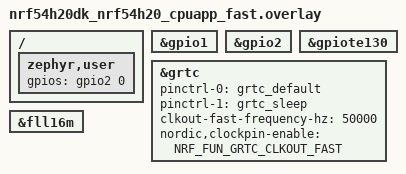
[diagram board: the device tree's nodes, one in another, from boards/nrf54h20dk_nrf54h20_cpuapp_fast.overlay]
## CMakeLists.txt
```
# SPDX-License-Identifier: LicenseRef-Nordic-5-Clause

cmake_minimum_required(VERSION 3.20.0)

find_package(Zephyr REQUIRED HINTS $ENV{ZEPHYR_BASE})
project(grtc_clk_out)

FILE(GLOB app_sources src/*.c)
target_sources(app PRIVATE ${app_sources})
```

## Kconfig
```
#
# Copyright (c) 2025 Nordic Semiconductor ASA
#
# SPDX-License-Identifier: LicenseRef-Nordic-5-Clause
#


config TEST_GRTC_FREQUENCY
	int "Expected frequency (Hz) at GRTC output pin"
	default 32768
	help
	  GRTC can output clock signal on dedicated pin.
	  This can be 32768 Hz signal or fast clock which is
	  16 MHz divided by (1..255 * 2).

config TEST_GRTC_TOLERANCE
	int "Amount of additional/missing clock edges"
	default 100
	help
	  Define tolerance for expected number of clock edges
	  counted during 1 second interval.

source "Kconfig.zephyr"
```

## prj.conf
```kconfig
CONFIG_ZTEST=y
CONFIG_SPEED_OPTIMIZATIONS=y
CONFIG_CLOCK_CONTROL=y
```

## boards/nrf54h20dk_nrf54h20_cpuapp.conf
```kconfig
CONFIG_NRF_REGTOOL_VERBOSITY=2
```

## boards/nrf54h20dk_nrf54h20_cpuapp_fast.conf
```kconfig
CONFIG_TEST_GRTC_FREQUENCY=50000
CONFIG_TEST_GRTC_TOLERANCE=500
```

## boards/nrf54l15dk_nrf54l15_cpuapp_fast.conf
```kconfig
CONFIG_TEST_GRTC_FREQUENCY=40000
CONFIG_TEST_GRTC_TOLERANCE=400
```

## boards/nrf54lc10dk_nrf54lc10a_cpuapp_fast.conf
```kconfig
nrf54lv10dk_nrf54lv10a_cpuapp_fast.conf
```

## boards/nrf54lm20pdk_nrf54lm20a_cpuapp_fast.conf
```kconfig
CONFIG_TEST_GRTC_FREQUENCY=32000
CONFIG_TEST_GRTC_TOLERANCE=320
```

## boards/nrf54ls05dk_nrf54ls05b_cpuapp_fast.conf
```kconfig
CONFIG_TEST_GRTC_FREQUENCY=32000
CONFIG_TEST_GRTC_TOLERANCE=360
```

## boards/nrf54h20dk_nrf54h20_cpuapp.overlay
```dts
/*
 * Copyright (c) 2025 Nordic Semiconductor ASA
 *
 * SPDX-License-Identifier: LicenseRef-Nordic-5-Clause
 */

/* Required loopback between:
 * GPIO P0.3 and P0.1 (GRTC 32k; defined @board; no other option)
 */

/ {
	zephyr,user {
		gpios = <&gpio0 3 GPIO_ACTIVE_HIGH>;  /* Connect to dedicated GRTC output */
	};
};

&gpio0 {
	status = "okay";
};

&gpiote130 {
	status = "okay";
};

&grtc {
	pinctrl-0 = <&grtc_default>;
	pinctrl-1 = <&grtc_sleep>;
	pinctrl-names = "default", "sleep";
	clkout-32k;
};

&fll16m {
	status = "okay";
};
```

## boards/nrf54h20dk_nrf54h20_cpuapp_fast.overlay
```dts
/*
 * Copyright (c) 2025 Nordic Semiconductor ASA
 *
 * SPDX-License-Identifier: LicenseRef-Nordic-5-Clause
 */

/* Required loopback between:
 * GPIO P2.0 and P1.8 (GRTC fast; defined @board; can be changed to P2.5 or P9.0)
 */

/ {
	zephyr,user {
		gpios = <&gpio2 0 GPIO_ACTIVE_HIGH>;  /* Connect to dedicated GRTC output */
	};
};

&gpio1 {
	status = "okay";
};

&gpio2 {
	status = "okay";
};

&gpiote130 {
	status = "okay";
};

&grtc {
	pinctrl-0 = <&grtc_default>;
	pinctrl-1 = <&grtc_sleep>;
	pinctrl-names = "default", "sleep";
	clkout-fast-frequency-hz = <50000>;  /* 16 MHz / (160 * 2) */
	nordic,clockpin-enable = <NRF_FUN_GRTC_CLKOUT_FAST>;
};

&fll16m {
	status = "okay";
};
```

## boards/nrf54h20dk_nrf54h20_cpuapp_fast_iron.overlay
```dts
/*
 * Copyright (c) 2025 Nordic Semiconductor ASA
 *
 * SPDX-License-Identifier: LicenseRef-Nordic-5-Clause
 */

/* Required loopback between:
 * GPIO P2.0 and P1.8 (GRTC fast; defined @board; can be changed to P2.5 or P9.0)
 */

/ {
	zephyr,user {
		gpios = <&gpio2 0 GPIO_ACTIVE_HIGH>;  /* Connect to dedicated GRTC output */
	};
};

&gpio1 {
	status = "okay";
};

&gpio2 {
	status = "okay";
};

&gpiote130 {
	status = "okay";
};

&grtc {
	pinctrl-0 = <&grtc_default>;
	pinctrl-1 = <&grtc_sleep>;
	pinctrl-names = "default", "sleep";
	clkout-fast-frequency-hz = <50000>;  /* 16 MHz / (160 * 2) */
	nordic,clockpin-enable = <NRF_FUN_GRTC_CLKOUT_FAST>;
};
```

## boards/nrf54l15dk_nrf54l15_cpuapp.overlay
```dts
/*
 * Copyright (c) 2025 Nordic Semiconductor ASA
 *
 * SPDX-License-Identifier: LicenseRef-Nordic-5-Clause
 */

/* Required loopback between:
 * GPIO P0.0 and P0.4 (GRTC 32k; defined @board; no other option)
 */

/ {
	zephyr,user {
		gpios = <&gpio0 0 GPIO_ACTIVE_HIGH>;  /* Connect to dedicated GRTC output */
	};
};

&gpio0 {
	status = "okay";
};

&gpiote30 {
	status = "okay";
};

&grtc {
	pinctrl-0 = <&grtc_default>;
	pinctrl-1 = <&grtc_sleep>;
	pinctrl-names = "default", "sleep";
	clkout-32k;
};
```

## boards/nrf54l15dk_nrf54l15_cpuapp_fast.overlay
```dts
/*
 * Copyright (c) 2025 Nordic Semiconductor ASA
 *
 * SPDX-License-Identifier: LicenseRef-Nordic-5-Clause
 */

/* Required loopback between:
 * GPIO P1.9 and P1.8 (GRTC fast; defined @board; no other option)
 */

/ {
	zephyr,user {
		gpios = <&gpio1 9 GPIO_ACTIVE_HIGH>;  /* Connect to dedicated GRTC output */
	};
};

&gpio1 {
	status = "okay";
};

&gpiote20 {
	status = "okay";
};

&grtc {
	pinctrl-0 = <&grtc_default>;
	pinctrl-1 = <&grtc_sleep>;
	pinctrl-names = "default", "sleep";
	clkout-fast-frequency-hz = <40000>;  /* 16 MHz / (200 * 2) */
};
```

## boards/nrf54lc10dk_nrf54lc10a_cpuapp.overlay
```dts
/*
 * Copyright (c) 2026 Nordic Semiconductor ASA
 *
 * SPDX-License-Identifier: LicenseRef-Nordic-5-Clause
 */

/* Required loopback between:
 * GPIO P1.16 and P0.4 (GRTC 32k; defined @board; no other option)
 */

/ {
	zephyr,user {
		gpios = <&gpio1 16 GPIO_ACTIVE_HIGH>;  /* Connect to dedicated GRTC output */
	};
};

&gpio1 {
	status = "okay";
};

&grtc {
	pinctrl-0 = <&grtc_default>;
	pinctrl-1 = <&grtc_sleep>;
	pinctrl-names = "default", "sleep";
	clkout-32k;
};
```

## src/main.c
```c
/*
 * Copyright (c) 2025 Nordic Semiconductor ASA
 *
 * SPDX-License-Identifier: LicenseRef-Nordic-5-Clause
 */

#include <zephyr/kernel.h>
#include <zephyr/ztest.h>
#include <zephyr/drivers/gpio.h>
#include <zephyr/drivers/clock_control/nrf_clock_control.h>


static volatile uint32_t count_clk;

static struct gpio_callback clk_cb_data;
static const struct gpio_dt_spec gpio_clk_spec =
	GPIO_DT_SPEC_GET_BY_IDX(DT_PATH(zephyr_user), gpios, 0);

#define GRTC_NODE DT_NODELABEL(grtc)

/* SoCs without an fll16m instance take the HFCLK from the nordic,nrf-clock block,
 * exposed as either an hfclk or an xo node depending on the SoC.
 */
#define HAS_NRF_CLOCK_HFCLK                                                                        \
	(DT_HAS_COMPAT_STATUS_OKAY(nordic_nrf_clock_hfclk) ||                                      \
	 DT_HAS_COMPAT_STATUS_OKAY(nordic_nrf_clock_xo))

#if DT_NODE_HAS_PROP(GRTC_NODE, clkout_fast_frequency_hz)
static struct onoff_client clk_cli;
static volatile bool clock_requested;

/* Callback for clock request. */
static void clock_started_callback(struct onoff_manager *mgr,
				   struct onoff_client *cli,
				   uint32_t state,
				   int res)
{
	(void)mgr;
	(void)cli;
	(void)state;
	(void)res;

	clock_requested = true;
}
#if DT_NODE_HAS_STATUS_OKAY(DT_NODELABEL(fll16m))
#define NODE_HFCLK      DT_NODELABEL(fll16m)
#define HFCLK_FREQUENCY DT_PROP_OR(NODE_HFCLK, frequency, 0)
static const struct device *clk_dev = DEVICE_DT_GET(NODE_HFCLK);
static const struct nrf_clock_spec fll16m_spec = {
	.frequency = HFCLK_FREQUENCY,
};
static const struct nrf_clock_spec *clk_spec = &fll16m_spec;

#elif HAS_NRF_CLOCK_HFCLK
#if defined(CONFIG_CLOCK_CONTROL_NRF)
static struct onoff_manager *clk_mgr;
#else
static const struct device *clk_dev = DEVICE_DT_GET_ONE(COND_CODE_1(NRF_CLOCK_HAS_HFCLK,
								    (nordic_nrf_clock_hfclk),
								    (nordic_nrf_clock_xo)));
static const struct nrf_clock_spec *clk_spec;
#endif
#endif

static int hf_clock_request(void)
{
	sys_notify_init_callback(&clk_cli.notify, clock_started_callback);
#if DT_NODE_HAS_STATUS_OKAY(DT_NODELABEL(fll16m)) || HAS_NRF_CLOCK_HFCLK
#if defined(CONFIG_CLOCK_CONTROL_NRF)
	clock_control_subsys_t subsys = CLOCK_CONTROL_NRF_SUBSYS_HF;

	clk_mgr = z_nrf_clock_control_get_onoff(subsys);
	return onoff_request(clk_mgr, &clk_cli);
#else
	return nrf_clock_control_request(clk_dev, clk_spec, &clk_cli);
#endif
#endif
	return -ENOTSUP;
}

static int hf_clock_release(void)
{
#if DT_NODE_HAS_STATUS_OKAY(DT_NODELABEL(fll16m)) || HAS_NRF_CLOCK_HFCLK
#if defined(CONFIG_CLOCK_CONTROL_NRF)
	return onoff_release(clk_mgr);
#else
	return nrf_clock_control_release(clk_dev, clk_spec);
#endif
#endif
	return -ENOTSUP;
}
#endif /* DT_NODE_HAS_PROP(GRTC_NODE, clkout_fast_frequency_hz) */

/* ISR that counts rising edges on the CLK signal. */
static void gpio_clk_isr(const struct device *dev, struct gpio_callback *cb, uint32_t pins)
{
	if (pins & BIT(gpio_clk_spec.pin)) {
		count_clk++;
	}
}

/** @brief Check that there are edges on GRTC clock output pin.
 *
 * Verify that CLK signal can be output from GRTC.
 */
ZTEST(drivers_grtc_clk_out, test_grtc_clk_output)
{
	uint32_t min = CONFIG_TEST_GRTC_FREQUENCY - CONFIG_TEST_GRTC_TOLERANCE;
	uint32_t max = CONFIG_TEST_GRTC_FREQUENCY + CONFIG_TEST_GRTC_TOLERANCE;
	uint32_t temp;

	TC_PRINT("GRTC CLK test starts\n");
	TC_PRINT("Frequency = %u\n", CONFIG_TEST_GRTC_FREQUENCY);
	TC_PRINT("Tolerance = %u clock edges\n", CONFIG_TEST_GRTC_TOLERANCE);

#if DT_NODE_HAS_PROP(GRTC_NODE, clkout_fast_frequency_hz)
	int ret = hf_clock_request();

	zassert_true(ret >= 0, "Failed to request clock.");
	k_msleep(20);
	zassert_true(clock_requested == true, "Failed to request clock.");
#endif

	count_clk = 0;
	k_msleep(1000);
	temp = count_clk;

#if DT_NODE_HAS_PROP(GRTC_NODE, clkout_fast_frequency_hz)
	ret = hf_clock_release();
	zassert_true(ret >= 0, "Failed to release clock.");
#endif

	/* Verify number of edges on CLK (with some tolerance) */
	zassert_true(temp >= min,
		"CLK has %u rising edges, while at least %u is expected.",
		temp, min);

	zassert_true(temp <= max,
		"CLK has %u rising edges, while no more than %u is expected.",
		temp, max);

	TC_PRINT("In ~1 second, there were %d rising edges\n", temp);
}

static void *suite_setup(void)
{
	int ret;

	/* Configure GPIO used to count CLK edges. */
	ret = gpio_is_ready_dt(&gpio_clk_spec);
	zassert_equal(ret, true, "gpio_clk_spec not ready (ret %d)", ret);
	ret = gpio_pin_configure_dt(&gpio_clk_spec, GPIO_INPUT);
	zassert_equal(ret, 0, "failed to configure input pin gpio_clk_spec (err %d)", ret);
	ret = gpio_pin_interrupt_configure_dt(&gpio_clk_spec, GPIO_INT_EDGE_RISING);
	zassert_equal(ret, 0, "failed to configure gpio_clk_spec interrupt (err %d)", ret);
	gpio_init_callback(&clk_cb_data, gpio_clk_isr, BIT(gpio_clk_spec.pin));
	gpio_add_callback(gpio_clk_spec.port, &clk_cb_data);

	return 0;
}

ZTEST_SUITE(drivers_grtc_clk_out, NULL, suite_setup, NULL, NULL, NULL);
```
